# NANO100AN_v1 register map
File version: 1.0
Registers are 32-bit, read-write, reset 0x0 unless marked. A register's access mark holds for its fields unless they carry their own. Offsets are from the block's base; [hi:lo] are bit positions; 'fields as' and 'values as' point back to an identical list.

## I2C0 — I2C Register Map
Base 0x40020000
Same registers: I2C1 0x40120000
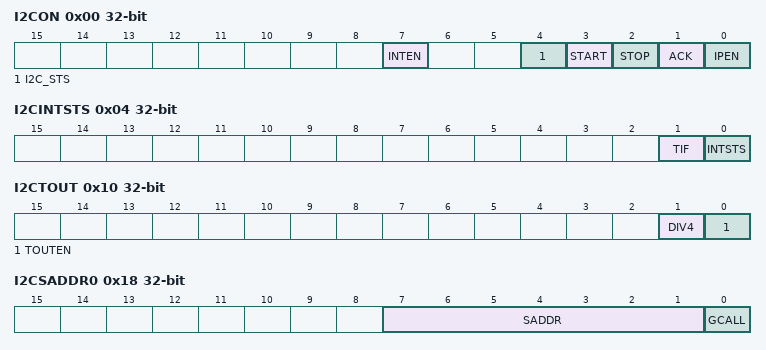
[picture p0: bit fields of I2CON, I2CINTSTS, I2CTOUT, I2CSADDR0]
0x00 I2CON — I2C Control Register
  [7] INTEN — Interrupt Enable Control
    0=I2C interrupt Disabled; 1=I2C interrupt Enabled
  [4] I2C_STS — I2C Status. When a new state is present in the I2CSTATUS register, if the INTEN bit is set, the I2C interrupt is requested. It must write one by software to this bit after the I2CINTSTS[0] is set to 1 and the I2C protocol function will go ahead until the STOP is active or the IPEN is disabled.
    0=I2C's Status disabled and the I2C protocol function will go ahead; 1=I2C's Status active
  [3] START — I2C START Command. Setting this bit to 1 to enter Master mode, the device sends a START or repeat START condition to bus when the bus is free and it will be cleared to 0 after the START command is active and the STATUS has been updated.
    0=After START or repeat START is active; 1=Sends a START or repeat START condition to bus
  [2] STOP — I2C STOP Control Bit. In Master mode, set this bit to 1 to transmit a STOP condition to bus then the controller will check the bus condition if a STOP condition is detected and this bit will be cleared by hardware automatically. In Slave mode, set this bit to 1 to reset the controller to the defined "not addressed" Slave mode. This means it is NO LONGER in the slave receiver mode to receive data from the master transmit device.
    0=Will be cleared by hardware automatically if a STOP condition is detected; 1=Sends a STOP condition to bus in Master mode or reset the controller to "not addressed" in Slave mode
  [1] ACK — Assert Acknowledge Control Bit
    0=When this bit is set to 0 prior to address or data received, a Not acknowledged (high level to SDA) will be returned during the acknowledge clock pulse; 1=When this bit is set to 1 prior to address or data received, an acknowledged will be returned during the acknowledge clock pulse on the SCL line when (a). A slave is acknowledging the address sent from master. (b). The receiver devices are acknowledging the data sent by transmitter
  [0] IPEN — I2C Function Enable Control
    0=I2C function Disabled; 1=I2C function Enabled
0x04 I2CINTSTS — I2C Interrupt Status Register
  [1] TIF — Time-Out Status
    0=No Time-out flag. Software can cleat this flag; 1=Time-Out flag active and it is set by hardware. It can interrupt CPU when INTEN bit is set
  [0] INTSTS — I2C STATUS's Interrupt Status
    0=No bus event occurred; 1=New state is presented in the I2CSTATUS. Software can write 1 to cleat this bit
0x08 I2CSTATUS ro reset 0xF8
  [7:0] STATUS — I2C Status Bits (Read Only). Indicates the current status code of the bus information. The detail information about the status is described in the sections of I2C protocol register and operation mode.
0x0C I2CDIV — I2C Clock Divided Register
  [7:0] CLK_DIV — I2C Clock Divided Bits. Note: the minimum value of CLK_DIV is 4.
0x10 I2CTOUT — I2C Time Out Counter Register
  [1] DIV4 — Time-Out Counter Input Clock Divider By 4. When Enabled, the time-out period is extended 4 times.
    0=Disabled; 1=Enabled
  [0] TOUTEN — Time-Out Counter Enable/Disable Control. When set this bit to enable, the 14 bits time-out counter will start counting when INTSTS (I2CINTSTS[0]) is cleared. Setting flag STAINTSTS to high or the falling edge of I2C clock or stop signal will reset counter and re-start up counting after INTSTS is cleared.
    0=Disabled; 1=Enabled
0x14 I2CDATA
  [7:0] DATA — I2C Data Bits. The DATA contains a byte of serial data to be transmitted or a byte which has just been received. Note: Refer to Data register section for more detail information.
0x18 I2CSADDR0 — Slave Address Register 0
  [7:1] SADDR — I2C Salve Address Bits. The content of this register is irrelevant when the device is in Master mode. In the Slave mode, the seven most significant bits must be loaded with the device's own address. The device will react if either of the address is matched.
  [0] GCALL — General Call Function. Note: Refer to Address Register section for more detail information..
    0=General Call Function Disabled; 1=General Call Function Enabled
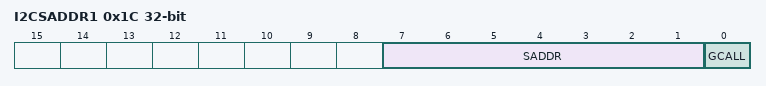
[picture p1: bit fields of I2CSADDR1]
0x1C I2CSADDR1 — Slave Address Register 1
  fields as I2CSADDR0
0x28 I2CSAMASK0 — Slave Address Mask Register 0
  [7:1] SAMASK — I2C Slave Address Mask Bits
    0=Mask disable (the received corresponding register bit should be exact the same as address register); 1=Mask enable (the received corresponding address bit is don't care)
0x2C I2CSAMASK1 — Slave Address Mask Register 1
  fields as I2CSAMASK0
